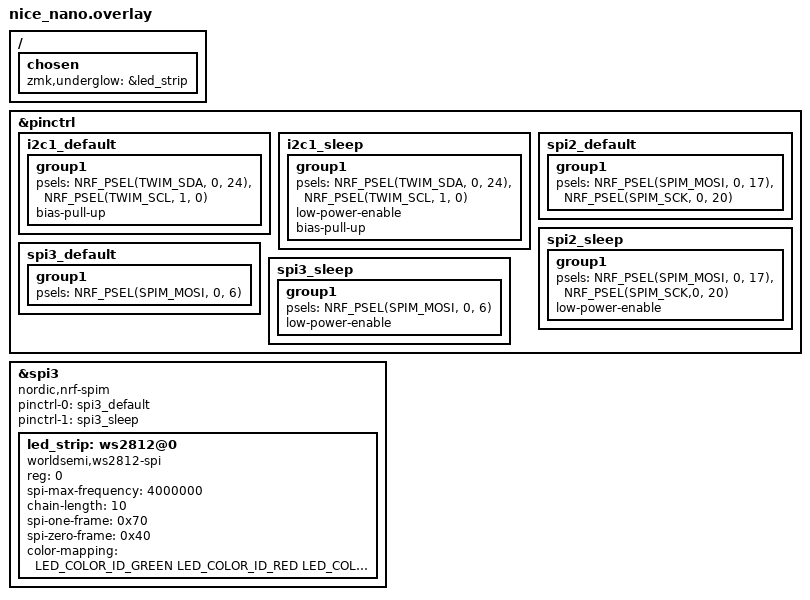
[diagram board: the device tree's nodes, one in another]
#include <dt-bindings/led/led.h>

&pinctrl {
    i2c1_default: i2c1_default {
        group1 {
            psels = <NRF_PSEL(TWIM_SDA, 0, 24)>,
	    <NRF_PSEL(TWIM_SCL, 1, 0)>;
	    bias-pull-up;
        };
    };

    i2c1_sleep: i2c1_sleep {
        group1 {
            psels = <NRF_PSEL(TWIM_SDA, 0, 24)>,
	    <NRF_PSEL(TWIM_SCL, 1, 0)>;
            low-power-enable;
	    bias-pull-up;
        };
    };

    spi2_default: spi2_default {
				group1 {
				psels = <NRF_PSEL(SPIM_MOSI, 0, 17)>,
				<NRF_PSEL(SPIM_SCK, 0, 20)>;
				};
		};
	
    spi2_sleep: spi2_sleep {
				group1 {
					psels = <NRF_PSEL(SPIM_MOSI, 0, 17)>,
					<NRF_PSEL(SPIM_SCK,0, 20)>;
					low-power-enable;
				};
		};
   spi3_default: spi3_default {
        group1 {
            psels = <NRF_PSEL(SPIM_MOSI, 0, 6)>;
        };
    };

    spi3_sleep: spi3_sleep {
        group1 {
            psels = <NRF_PSEL(SPIM_MOSI, 0, 6)>;
            low-power-enable;
        };
    };
};


&spi3 {
    compatible = "nordic,nrf-spim";
    status = "okay";

    pinctrl-0 = <&spi3_default>;
    pinctrl-1 = <&spi3_sleep>;
    pinctrl-names = "default", "sleep";

    led_strip: ws2812@0 {
        compatible = "worldsemi,ws2812-spi";

        /* SPI */
        reg = <0>; /* ignored, but necessary for SPI bindings */
        spi-max-frequency = <4000000>;

        /* WS2812 */
        chain-length = <10>; /* arbitrary; change at will */
        spi-one-frame = <0x70>;
        spi-zero-frame = <0x40>;

        color-mapping = <LED_COLOR_ID_GREEN LED_COLOR_ID_RED LED_COLOR_ID_BLUE>;
    };
};

/ {
    chosen {
        zmk,underglow = &led_strip;
    };
};
